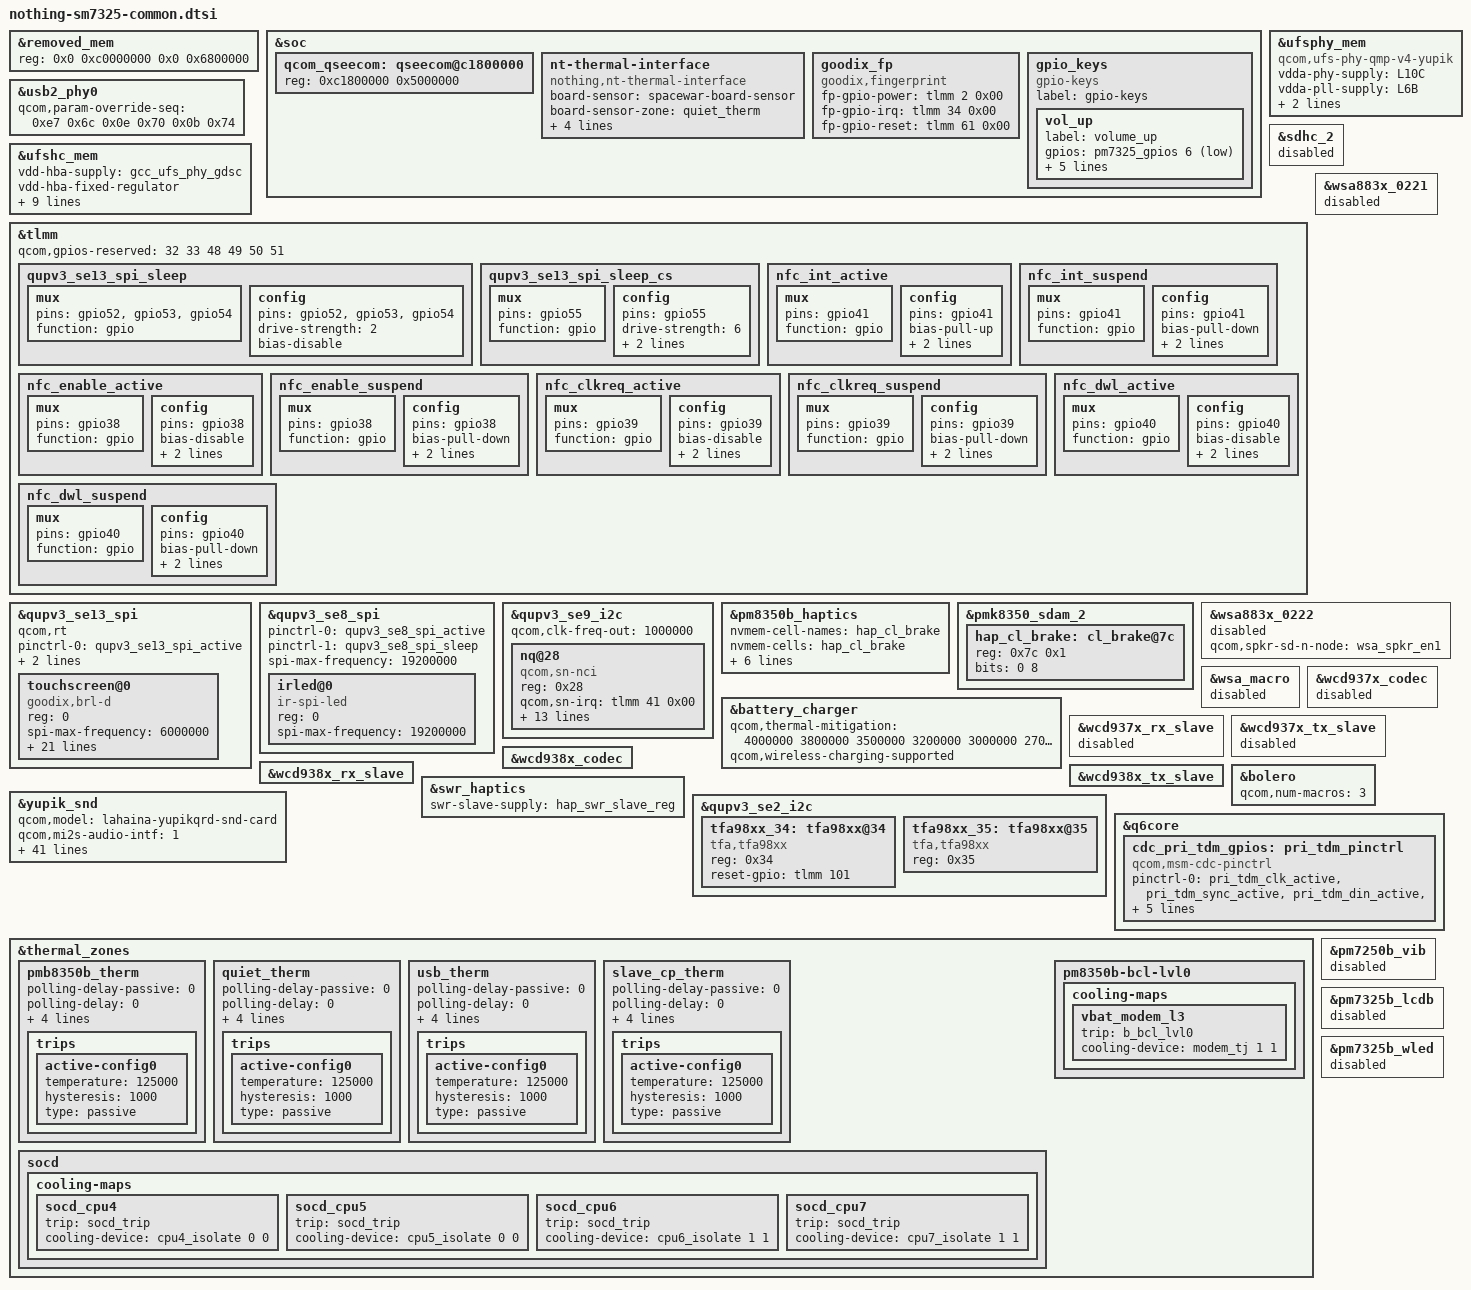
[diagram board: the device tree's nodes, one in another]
// SPDX-License-Identifier: GPL-2.0-only
// nothing-sm7325-common.dtsi
// Nothing Phone (1) "spacewar" — Qualcomm SM7325 (Yupik) common board config

#include "yupik-abra-common-overlay.dtsi"
#include "display/nothing-sm7325-sde-display.dtsi"
#include <dt-bindings/gpio/gpio.h>
#include <dt-bindings/input/input.h>
#include <dt-bindings/iio/qcom,spmi-adc7-pm7325.h>
#include <dt-bindings/iio/qcom,spmi-adc7-smb139x.h>
#include <dt-bindings/iio/qcom,spmi-adc7-pm8350b.h>

/* fingerprint/secure app region */
&removed_mem {
	reg = <0x0 0xc0000000 0x0 0x6800000>;
};

&soc {
	qcom_qseecom: qseecom@c1800000 {
		reg = <0xc1800000 0x5000000>;
		reg-names = "secapp-region";
	};

	nt-thermal-interface {
		compatible = "nothing,nt-thermal-interface";
		board-sensor = "spacewar-board-sensor";
		/* zones the driver live-reads for board_sensor_temp */
		board-sensor-zone = "quiet_therm";
		board-sensor-second-zone = "usb_therm";
		qcom,display-panels = <&dsi_rm692e5_visionox_amoled_120hz_cmd
					&dsi_r66451_amoled_144hz_video_cphy>;
	};

	/*
	 * FINGERPRINT — under-display optical Goodix.
	 * GPIOs verified against stock spacewar dtbo
	 * (power=gpio2, irq=gpio34, reset=gpio61).
	 */
	goodix_fp {
		compatible = "goodix,fingerprint";
		fp-gpio-power = <&tlmm 2 0x00>;
		fp-gpio-irq = <&tlmm 34 0x00>;
		fp-gpio-reset = <&tlmm 61 0x00>;
		status = "ok";
	};
};

/* =====================================================================
 * 2. USB
 * ===================================================================== */

&usb2_phy0 {
	qcom,param-override-seq =
		<0xe7 0x6c  	/* override_x0 */
		 0x0e 0x70  	/* override_x1 */
		 0x0b 0x74>;	/* override x2 */
};

/*
 * (qcom,msm-mbhc-usbc-audio-supported = <1> in yupik_snd below).
 */

/* =====================================================================
 * 3. UFS
 * ===================================================================== */

&ufsphy_mem {
	compatible = "qcom,ufs-phy-qmp-v4-yupik";

	vdda-phy-supply = <&L10C>;
	vdda-pll-supply = <&L6B>;
	vdda-phy-max-microamp = <97500>;
	vdda-pll-max-microamp = <18400>;

	status = "ok";
};

&ufshc_mem {
	vdd-hba-supply = <&gcc_ufs_phy_gdsc>;
	vdd-hba-fixed-regulator;

	vcc-supply = <&L7B>;
	vcc-voltage-level = <2952000 2952000>;
	vcc-low-voltage-sup;
	vcc-max-microamp = <800000>;

	/*
	 * vccq (L9B) also controls the eLDO supplying VCCQ2 (UFS2.2).
	 * Do not change/remove these entries.
	 */
	vccq-supply = <&L9B>;
	vccq-max-microamp = <900000>;
	vccq-min-microamp = <10000>;

	qcom,vddp-ref-clk-supply = <&L9B>;
	qcom,vddp-ref-clk-max-microamp = <100>;

	status = "ok";
};

/* Phone (1) has no SD slot */
&sdhc_2 {
	status = "disabled";
};

&tlmm {
	qcom,gpios-reserved =  <32 33 48 49 50 51>;

	/* --- QUPV3 SE13 SPI (touch) sleep state --- */
	qupv3_se13_spi_sleep: qupv3_se13_spi_sleep {
		mux {
			pins = "gpio52", "gpio53", "gpio54";
			function = "gpio";
		};
		config {
			pins = "gpio52", "gpio53", "gpio54";
			drive-strength = <2>;
			bias-disable;
		};
	};

	qupv3_se13_spi_sleep_cs: qupv3_se13_spi_sleep_cs {
		mux {
			pins = "gpio55";
			function = "gpio";
		};
		config {
			pins = "gpio55";
			drive-strength = <6>;
			bias-disable;
			output-high;
		};
	};

	/* --- NFC --- */
	nfc_int_active: nfc_int_active {
		mux { pins = "gpio41"; function = "gpio"; };
		config { pins = "gpio41"; bias-pull-up; drive-strength = <2>; input-enable; };
	};
	nfc_int_suspend: nfc_int_suspend {
		mux { pins = "gpio41"; function = "gpio"; };
		config { pins = "gpio41"; bias-pull-down; drive-strength = <2>; input-enable; };
	};
	nfc_enable_active: nfc_enable_active {
		mux { pins = "gpio38"; function = "gpio"; };
		config { pins = "gpio38"; bias-disable; drive-strength = <2>; output-low; };
	};
	nfc_enable_suspend: nfc_enable_suspend {
		mux { pins = "gpio38"; function = "gpio"; };
		config { pins = "gpio38"; bias-pull-down; drive-strength = <2>; output-low; };
	};
	nfc_clkreq_active: nfc_clkreq_active {
		mux { pins = "gpio39"; function = "gpio"; };
		config { pins = "gpio39"; bias-disable; drive-strength = <2>; input-enable; };
	};
	nfc_clkreq_suspend: nfc_clkreq_suspend {
		mux { pins = "gpio39"; function = "gpio"; };
		config { pins = "gpio39"; bias-pull-down; drive-strength = <2>; input-enable; };
	};
	nfc_dwl_active: nfc_dwl_active {
		mux { pins = "gpio40"; function = "gpio"; };
		config { pins = "gpio40"; bias-disable; drive-strength = <2>; output-low; };
	};
	nfc_dwl_suspend: nfc_dwl_suspend {
		mux { pins = "gpio40"; function = "gpio"; };
		config { pins = "gpio40"; bias-pull-down; drive-strength = <2>; output-low; };
	};

	/*
	 * NOTE(resolved): &key_vol_up_default does NOT exist on Yupik
	 * (only in lahaina/pm8150/sa8155 pmic overlays) — gpio_keys stays
	 * pinctrl-less, matching stock behavior.
	 */
};

&qupv3_se13_spi {
	status = "ok";
	qcom,rt;
	pinctrl-names = "default", "sleep";
	pinctrl-0 = <&qupv3_se13_spi_active>;	/* from yupik base */
	pinctrl-1 = <&qupv3_se13_spi_sleep &qupv3_se13_spi_sleep_cs>;
	#address-cells = <1>;
	#size-cells = <0>;

	touchscreen@0 {
		compatible = "goodix,brl-d", "focaltech,fts_ts";
		reg = <0>;
		spi-max-frequency = <6000000>;

		panel = <&dsi_rm692e5_visionox_amoled_120hz_cmd
			 &dsi_r66451_amoled_144hz_video_cphy>;

		/* shared rails */
		vdd-supply = <&L3C>;		/* fts AVDD 3.3V */
		avdd-supply = <&L3C>;		/* goodix AVDD  */
		iovdd-supply = <&L8C>;		/* both, 1.8V   */

		/* Goodix */
		goodix,avdd-name = "avdd";
		goodix,iovdd-name = "iovdd";
		goodix,reset-gpio = <&tlmm 105 0x00>;
		goodix,irq-gpio = <&tlmm 81 0x2800>;
		goodix,irq-flags = <2>;
		goodix,panel-max-x = <1080>;
		goodix,panel-max-y = <2400>;
		goodix,panel-max-w = <255>;
		goodix,panel-max-p = <4096>;
		goodix,pen-enable;
		goodix,firmware-name = "goodix_firmware.bin";
		goodix,config-name = "goodix_cfg_group.bin";

		/* Focaltech */
		focaltech,reset-gpio = <&tlmm 105 0x00>;
		focaltech,irq-gpio = <&tlmm 81 0x2800>;
		focaltech,max-touch-number = <10>;
		focaltech,display-coords = <0 0 1080 2400>;
	};
};

&qupv3_se8_spi {
	status = "okay";
	pinctrl-names = "default", "sleep";
	pinctrl-0 = <&qupv3_se8_spi_active>;
	pinctrl-1 = <&qupv3_se8_spi_sleep>;
	spi-max-frequency = <19200000>;
	#address-cells = <1>;
	#size-cells = <0>;

	irled@0 {
		compatible = "ir-spi-led";
		reg = <0>;
		spi-max-frequency = <19200000>;
	};
};

&qupv3_se9_i2c {
	status = "ok";
	qcom,clk-freq-out = <1000000>;
	#address-cells = <1>;
	#size-cells = <0>;

	nq@28 {
		compatible = "qcom,sn-nci";
		reg = <0x28>;
		qcom,sn-irq = <&tlmm 41 0x00>;
		qcom,sn-ven = <&tlmm 38 0x00>;
		qcom,sn-firm = <&tlmm 40 0x00>;
		qcom,sn-clkreq = <&tlmm 39 0x00>;
		qcom,sn-vdd-1p8-supply = <&L18B>;
		qcom,sn-vdd-1p8-voltage = <1800000 1800000>;
		qcom,sn-vdd-1p8-current = <157000>;
		interrupt-parent = <&tlmm>;
		interrupts = <41 0>;
		interrupt-names = "nfc_irq";
		pinctrl-names = "nfc_active", "nfc_suspend";
		pinctrl-0 = <&nfc_int_active &nfc_enable_active
				&nfc_clkreq_active &nfc_dwl_active>;
		pinctrl-1 = <&nfc_int_suspend &nfc_enable_suspend
				&nfc_clkreq_suspend &nfc_dwl_suspend>;
	};
};

&pm8350b_haptics {
	nvmem-cell-names = "hap_cl_brake";
	nvmem-cells = <&hap_cl_brake>;
	nvmem-names = "hap_cfg_sdam";
	nvmem = <&pmk8350_sdam_46>;
	qcom,pbs-client = <&pm8350b_pbs2>;
	qcom,Vrms_mv = <1270>;
	qcom,vmax-mv = <9150>;
	qcom,lra-period-us = <5880>;
	status = "ok";
};

&pmk8350_sdam_2 {
	hap_cl_brake: cl_brake@7c {
		reg = <0x7c 0x1>;
		bits = <0 8>;
	};
};

&battery_charger {
	/* 15 steps -> cooling_device "battery" max_state=15 */
	qcom,thermal-mitigation = <4000000 3800000 3500000 3200000 3000000
				2700000 2500000 2200000 2000000 1700000
				1500000 1200000 1000000 800000 500000>;
	qcom,wireless-charging-supported;
};

/* ---- disable unused codecs/macros ---- */
&wsa883x_0221 { status = "disabled"; };

&wsa883x_0222 {
	qcom,spkr-sd-n-node = <&wsa_spkr_en1>;
	status = "disabled";
};

&wsa_macro { status = "disabled"; };

&wcd937x_codec { status = "disabled"; };
&wcd937x_rx_slave { status = "disabled"; };
&wcd937x_tx_slave { status = "disabled"; };

/* ---- enable what we actually have ---- */
&wcd938x_codec { status = "okay"; };
&wcd938x_rx_slave { status = "okay"; };
&wcd938x_tx_slave { status = "okay"; };

&swr_haptics {
	status = "okay";
	swr-slave-supply = <&hap_swr_slave_reg>;
};

&bolero { qcom,num-macros = <3>; };

/* ---- tfa98xx smart amps: speakers on PRIMARY MI2S RX ----
 * CPU dai "msm-dai-q6-mi2s.0" (see techpack/audio/asoc/msm_dailink.h: pri_mi2s_rx)
 * Addresses/channels verified against live device (i2c-1 = 0x988000).
 * Compatible verified against tfa98xx.c:5738 ("tfa,tfa98xx").
 * The driver only parses reset-gpio (tfa98xx.c:4118)
 */
&qupv3_se2_i2c {
	status = "okay";

	tfa98xx_34: tfa98xx@34 {
		compatible = "tfa,tfa98xx";
		reg = <0x34>;
		reset-gpio = <&tlmm 101 0>;
		status = "okay";
	};

	tfa98xx_35: tfa98xx@35 {
		compatible = "tfa,tfa98xx";
		reg = <0x35>;
		status = "okay";
	};
};

/*     sound card     */
&yupik_snd {
	qcom,model = "lahaina-yupikqrd-snd-card";

	/* ensure the MI2S backend links exist even with a custom dtbo */
	qcom,mi2s-audio-intf = <1>;

	qcom,audio-routing =
		"AMIC1", "Analog Mic1",
		"Analog Mic1", "MIC BIAS1",
		"AMIC2", "Analog Mic2",
		"Analog Mic2", "MIC BIAS2",
		"AMIC3", "Analog Mic3",
		"Analog Mic3", "MIC BIAS1",
		"AMIC4", "Analog Mic4",
		"Analog Mic4", "MIC BIAS1",
		"AMIC5", "Analog Mic5",
		"Analog Mic5", "MIC BIAS4",
		"TX DMIC0", "Digital Mic0",
		"Digital Mic0", "MIC BIAS1",
		"TX DMIC1", "Digital Mic1",
		"Digital Mic1", "MIC BIAS1",
		"TX DMIC2", "Digital Mic2",
		"Digital Mic2", "MIC BIAS3",
		"TX DMIC3", "Digital Mic3",
		"Digital Mic3", "MIC BIAS3",
		"TX DMIC4", "Digital Mic4",
		"Digital Mic4", "MIC BIAS4",
		"TX DMIC5", "Digital Mic5",
		"Digital Mic5", "MIC BIAS4",
		"IN1_HPHL", "HPHL_OUT",
		"IN2_HPHR", "HPHR_OUT",
		"IN3_AUX", "AUX_OUT",
		"HAP_IN", "PCM_OUT",
		"RX_TX DEC0_INP", "TX DEC0 MUX",
		"RX_TX DEC1_INP", "TX DEC1 MUX",
		"RX_TX DEC2_INP", "TX DEC2 MUX",
		"RX_TX DEC3_INP", "TX DEC3 MUX",
		"TX SWR_INPUT", "WCD_TX_OUTPUT",
		"VA SWR_INPUT", "VA_SWR_CLK",
		"VA SWR_INPUT", "WCD_TX_OUTPUT",
		"VA_AIF1 CAP", "VA_SWR_CLK",
		"VA_AIF2 CAP", "VA_SWR_CLK",
		"VA_AIF3 CAP", "VA_SWR_CLK",
		"VA DMIC0", "Digital Mic0",
		"VA DMIC1", "Digital Mic1",
		"VA DMIC2", "Digital Mic2",
		"VA DMIC3", "Digital Mic3",
		"VA DMIC4", "Digital Mic4",
		"VA DMIC5", "Digital Mic5",
		"VA DMIC0", "VA MIC BIAS1",
		"VA DMIC1", "VA MIC BIAS3",
		"VA DMIC2", "VA MIC BIAS4",
		"VA DMIC3", "VA MIC BIAS1",
		"VA DMIC4", "VA MIC BIAS3",
		"VA DMIC5", "VA MIC BIAS4";

	qcom,msm-mbhc-usbc-audio-supported = <1>;
	qcom,msm-mbhc-hphl-swh = <0>;
	qcom,msm-mbhc-gnd-swh = <0>;

	/* PRI_MI2S_RX binds "tfa98xx.1-0034/35" by name (msm_dailink.h). */
	asoc-codec = <&stub_codec>, <&bolero>,
		      <&wcd938x_codec>, <&swr_haptics>,
		      <&ext_disp_audio_codec>;
	asoc-codec-names = "msm-stub-codec.1", "bolero_codec",
			   "wcd938x_codec", "swr-haptics",
			   "msm-ext-disp-audio-codec-rx";
	qcom,wsa-max-devs = <0>;
	qcom,swr-dmic-max-devs = <0>;
};

/* pri-TDM pinctrl kept for the aux/TDM path */
&q6core {
	cdc_pri_tdm_gpios: pri_tdm_pinctrl {
		compatible = "qcom,msm-cdc-pinctrl";
		pinctrl-names = "aud_active", "aud_sleep";
		pinctrl-0 = <&pri_tdm_clk_active &pri_tdm_sync_active
			&pri_tdm_din_active &pri_tdm_dout_active>;
		pinctrl-1 = <&pri_tdm_clk_sleep &pri_tdm_sync_sleep
			&pri_tdm_din_sleep &pri_tdm_dout_sleep>;
		qcom,lpi-gpios;
		#gpio-cells = <0>;
	};
};

/*
 * yupik-atp.dtsi shows the pattern: &pmk8350_adc_tm needs io-channels +
 * child nodes with reg = <channel> for each used channel:
 *
 * &pmk8350_adc_tm {
 *	io-channels = <&pmk8350_vadc PM8350B_ADC7_AMUX_THM3_100K_PU>,
 *			<&pmk8350_vadc PM8350B_ADC7_AMUX_THM4_100K_PU>,
 *			<&pmk8350_vadc PM8350B_ADC7_GPIO2_100K_PU>,
 *			<&pmk8350_vadc PM8350_ADC7_AMUX_THM2_100K_PU>;
 *	io-channel-names = "pm8350b_thm3", "pm8350b_thm4",
 *			"pm8350b_gpio2", "pm8350_thm2";
 *
 *	pmb8350b_therm_channel { reg = <PM8350B_ADC7_AMUX_THM3_100K_PU>; };
 *	quiet_therm_channel  { reg = <PM8350B_ADC7_AMUX_THM4_100K_PU>; };
 *	usb_therm_channel    { reg = <PM8350B_ADC7_GPIO2_100K_PU>; };
 *	slave_cp_channel     { reg = <PM8350_ADC7_AMUX_THM2_100K_PU>; };
 * };
 *
 */

&thermal_zones {
	/* Nothing thermal-engine probes: user_space governor + wake-capable */

	pmb8350b_therm {
		polling-delay-passive = <0>;
		polling-delay = <0>;
		thermal-governor = "user_space";
		thermal-sensors = <&pmk8350_adc_tm PM8350B_ADC7_AMUX_THM3_100K_PU>;
		wake-capable-sensor;
		trips {
			active-config0 {
				temperature = <125000>;
				hysteresis = <1000>;
				type = "passive";
			};
		};
	};

	quiet_therm {
		polling-delay-passive = <0>;
		polling-delay = <0>;
		thermal-governor = "user_space";
		thermal-sensors = <&pmk8350_adc_tm PM8350B_ADC7_AMUX_THM4_100K_PU>;
		wake-capable-sensor;
		trips {
			active-config0 {
				temperature = <125000>;
				hysteresis = <1000>;
				type = "passive";
			};
		};
	};

	usb_therm {
		polling-delay-passive = <0>;
		polling-delay = <0>;
		thermal-governor = "user_space";
		thermal-sensors = <&pmk8350_adc_tm PM8350B_ADC7_GPIO2_100K_PU>;
		wake-capable-sensor;
		trips {
			active-config0 {
				temperature = <125000>;
				hysteresis = <1000>;
				type = "passive";
			};
		};
	};

	slave_cp_therm {
		polling-delay-passive = <0>;
		polling-delay = <0>;
		thermal-governor = "user_space";
		thermal-sensors = <&pmk8350_adc_tm PM8350_ADC7_AMUX_THM2_100K_PU>;
		wake-capable-sensor;
		trips {
			active-config0 {
				temperature = <125000>;
				hysteresis = <1000>;
				type = "passive";
			};
		};
	};

	/* SoD backplate mitigation (labels verified) */
	socd {
		cooling-maps {
			socd_cpu4 { trip = <&socd_trip>; cooling-device = <&cpu4_isolate 0 0>; };
			socd_cpu5 { trip = <&socd_trip>; cooling-device = <&cpu5_isolate 0 0>; };
			socd_cpu6 { trip = <&socd_trip>; cooling-device = <&cpu6_isolate 1 1>; };
			socd_cpu7 { trip = <&socd_trip>; cooling-device = <&cpu7_isolate 1 1>; };
		};
	};

	pm8350b-bcl-lvl0 {
		cooling-maps {
			vbat_modem_l3 { trip = <&b_bcl_lvl0>; cooling-device = <&modem_tj 1 1>; };
		};
	};
};

&soc {
	gpio_keys {
		compatible = "gpio-keys";
		label = "gpio-keys";
		/*
		 * pinctrl-less on purpose: &key_vol_up_default does not exist
		 * in the Yupik pmic tree (grep-verified; only lahaina/pm8150/
		 * sa8155 define it). PM7325 GPIO needs no pinctrl.
		 */
		vol_up {
			label = "volume_up";
			gpios = <&pm7325_gpios 6 GPIO_ACTIVE_LOW>;
			linux,input-type = <1>;
			linux,code = <KEY_VOLUMEUP>;
			gpio-key,wakeup;
			debounce-interval = <32>;
			linux,can-disable;
		};
	};
};

/* Phone (1) uses PM8350B HV haptics */
&pm7250b_vib {
	status = "disabled";
};

/* No LCD (OLED) — kill backlight drivers */
&pm7325b_lcdb {
	status = "disabled";
};

&pm7325b_wled {
	status = "disabled";
};
